# AT32F423xx_v2 register map
Vendor: Keil; Series: AT32F423; File version: 1.0
CPU: CM4 r0p1, little endian, no MPU, FPU, 4 interrupt priority bits
Registers are 32-bit, read-write, reset 0x0 unless marked. A register's access mark holds for its fields unless they carry their own. Offsets are from the block's base; [hi:lo] are bit positions.

## DEBUG — Debug support
Base 0xE0042000
0x00 IDCODE ro — DEBUG IDCODE
  [31:0] PID — Product ID
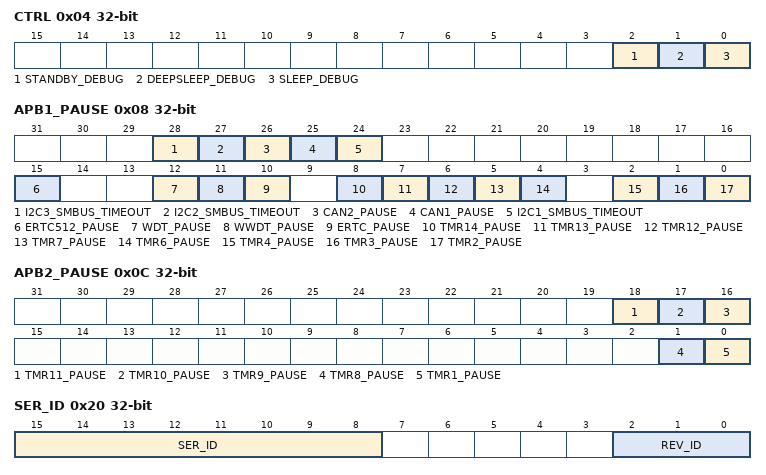
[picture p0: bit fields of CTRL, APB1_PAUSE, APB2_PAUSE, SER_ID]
0x04 CTRL — DEBUG CTRL
  [2] STANDBY_DEBUG, [1] DEEPSLEEP_DEBUG, [0] SLEEP_DEBUG
0x08 APB1_PAUSE — DEBUG APB1 PAUSE
  [28] I2C3_SMBUS_TIMEOUT, [27] I2C2_SMBUS_TIMEOUT, [26] CAN2_PAUSE, [25] CAN1_PAUSE, [24] I2C1_SMBUS_TIMEOUT, [15] ERTC512_PAUSE, [12] WDT_PAUSE, [11] WWDT_PAUSE, [10] ERTC_PAUSE, [8] TMR14_PAUSE, [7] TMR13_PAUSE, [6] TMR12_PAUSE, [5] TMR7_PAUSE, [4] TMR6_PAUSE, [2] TMR4_PAUSE, [1] TMR3_PAUSE, [0] TMR2_PAUSE
0x0C APB2_PAUSE — DEBUG APB2 PAUSE
  [18] TMR11_PAUSE, [17] TMR10_PAUSE, [16] TMR9_PAUSE, [1] TMR8_PAUSE, [0] TMR1_PAUSE
0x20 SER_ID ro — SERIES ID
  [15:8] SER_ID — series ID
  [2:0] REV_ID — version ID

## CRC — CRC calculation unit
Base 0x40023000
0x00 DT reset 0xFFFFFFFF — Data register
  [31:0] DT — Data Register
0x04 CDT — Common data register
  [0] CDT — Common Data
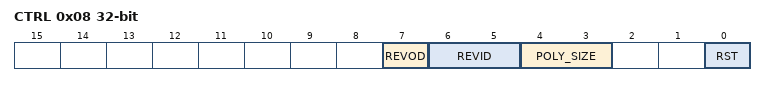
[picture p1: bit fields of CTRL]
0x08 CTRL — Control register
  [7] REVOD — Reverse output data
  [6:5] REVID — Reverse input data
  [4:3] POLY_SIZE — Polynomial size
  [0] RST — Reset bit
0x10 IDT reset 0xFFFFFFFF — Initial data register
  [31:0] IDT — Initial Data
0x14 POLY reset 0x4C11DB7 — Polynomial coefficient register
  [31:0] POLY — polynomial coefficient

## FLASH — Flash memory controler
Base 0x40023C00
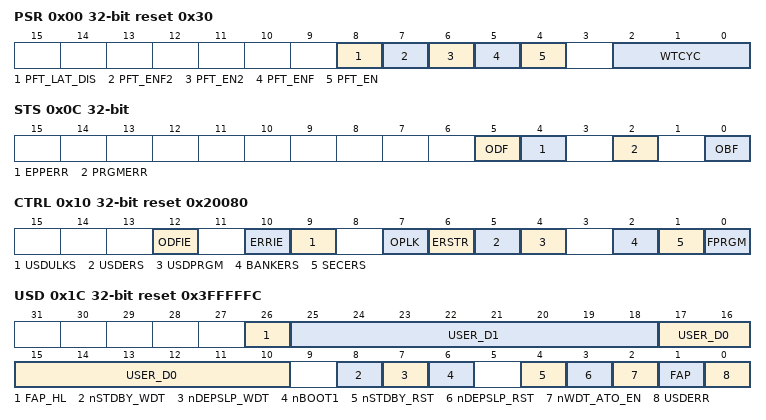
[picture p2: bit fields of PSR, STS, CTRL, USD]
0x00 PSR reset 0x30 — Performance selection register
  [8] PFT_LAT_DIS — Prefetch latency disable
  [7] PFT_ENF2 ro — Prefetch enabled flag 2
  [6] PFT_EN2 — Prefetch enable 2
  [5] PFT_ENF ro — Prefetch enabled flag
  [4] PFT_EN — Prefetch enable
  [2:0] WTCYC — Wait cycle
0x04 UNLOCK wo
  [31:0] UKVAL — Unlock key value
0x08 USD_UNLOCK wo
  [31:0] USD_UKVAL — User system data Unlock key value
0x0C STS — Status register
  [5] ODF — Operate done flag
  [4] EPPERR — Erase/program protection error
  [2] PRGMERR — program error
  [0] OBF ro — Operate busy flag
0x10 CTRL reset 0x20080 — Control register
  [12] ODFIE — Operation done flag interrupt enable
  [10] ERRIE — Error interrupt enable
  [9] USDULKS — User system data unlock success
  [7] OPLK — Operation lock
  [6] ERSTR — Erasing start
  [5] USDERS — User system data erase
  [4] USDPRGM — User system data program
  [2] BANKERS — Bank erase
  [1] SECERS — Sector erase
  [0] FPRGM — Flash program
0x14 ADDR wo — Address register
  [31:0] FA — Flash Address
0x1C USD ro reset 0x3FFFFFC — User system data register
  [26] FAP_HL — FAP high level
  [25:18] USER_D1 — User data 1
  [17:10] USER_D0 — User data 0
  [8] nSTDBY_WDT — Standby wdt stop count
  [7] nDEPSLP_WDT — Deepsleep wdt stop count
  [6] nBOOT1 — boot1
  [4] nSTDBY_RST — Standby reset
  [3] nDEPSLP_RST — Deepsleep reset
  [2] nWDT_ATO_EN — WDT auto enable
  [1] FAP — FLASH access protection
  [0] USDERR — User system data error
0x20 EPPS ro reset 0xFFFFFFFF — Erase/program protection status register
  [31:0] EPPS — Erase/program protection status
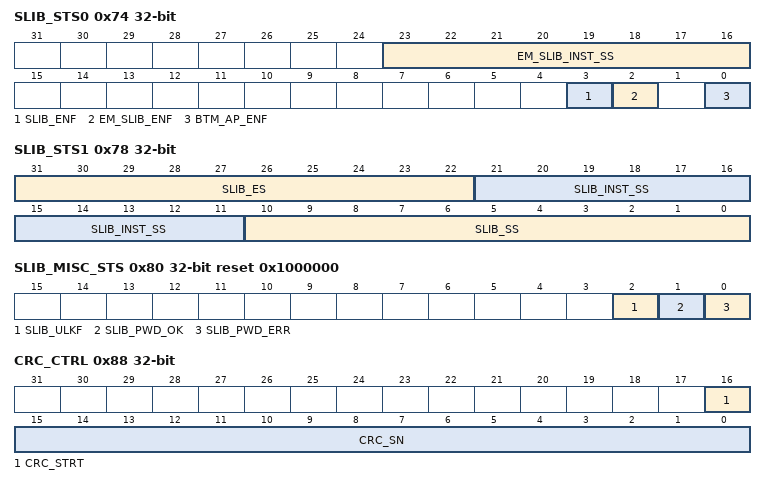
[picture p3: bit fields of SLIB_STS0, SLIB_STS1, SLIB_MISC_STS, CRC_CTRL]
0x74 SLIB_STS0 — sLib status 0 register
  [23:16] EM_SLIB_INST_SS — Extension memory sLib instruction start sector
  [3] SLIB_ENF — sLib enabled flag
  [2] EM_SLIB_ENF — Extension memory sLib enabled flag
  [0] BTM_AP_ENF — Boot memory store application code enabled flag
0x78 SLIB_STS1 — sLib status 1 register
  [31:22] SLIB_ES — sLib end sector
  [21:11] SLIB_INST_SS — sLib instruction start sector
  [10:0] SLIB_SS — sLib start sector
0x7C SLIB_PWD_CLR wo — SLIB password clear register
  [31:0] SLIB_PCLR_VAL — sLib password clear value
0x80 SLIB_MISC_STS reset 0x1000000 — sLib misc status register
  [2] SLIB_ULKF ro — sLib unlock flag
  [1] SLIB_PWD_OK ro — sLib password ok
  [0] SLIB_PWD_ERR ro — sLib password error
0x84 CRC_ADDR wo — Flash CRC data start address register
  [31:0] CRC_ADDR — CRC address
0x88 CRC_CTRL — Flash CRC controll register
  [16] CRC_STRT wo — CRC start
  [15:0] CRC_SN — CRC sector numbler
0x8C CRC_CHKR ro — FLASH CRC check result register
  [31:0] FCRC_OUT — CRC32 verification result of flash user code or SLIB code
0x160 SLIB_SET_PWD wo — sLib password setting register
  [31:0] SLIB_PSET_VAL — sLib password setting val
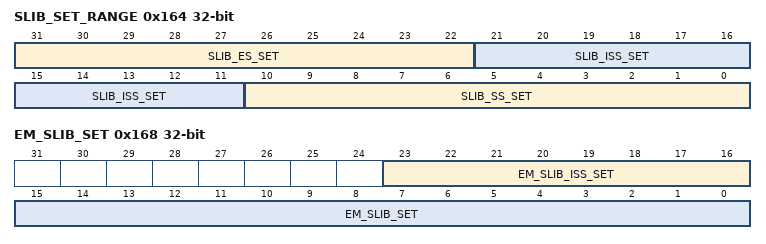
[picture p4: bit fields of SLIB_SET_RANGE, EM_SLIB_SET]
0x164 SLIB_SET_RANGE wo — Configure sLib range register
  [31:22] SLIB_ES_SET — sLib end sector setting
  [21:11] SLIB_ISS_SET — sLib instruction start sector setting
  [10:0] SLIB_SS_SET — sLib start sector setting
0x168 EM_SLIB_SET wo — Extension momery slib set register
  [23:16] EM_SLIB_ISS_SET — Extension memory sLib instruction start sector setting
  [15:0] EM_SLIB_SET — Extension memory sLib setting
0x16C BTM_MODE_SET wo — Boot memory mode setting register
  [7:0] BTM_MODE_SET — Boot memory mode setting
0x170 SLIB_UNLOCK wo
  [31:0] SLIB_UKVAL — sLib unlock key value

## Notices in the file
Copyright (C) 2012-2014 ARM Limited. All rights reserved.
Purpose: System Viewer Description (SVD) Example (Schema Version 1.1)
This is a description of a none-existent and incomplete device
for demonstration purposes only.
Redistribution and use in source and binary forms, with or without
modification, are permitted provided that the following conditions are met:
- Redistributions of source code must retain the above copyright
notice, this list of conditions and the following disclaimer.
- Redistributions in binary form must reproduce the above copyright
notice, this list of conditions and the following disclaimer in the
documentation and/or other materials provided with the distribution.
- Neither the name of ARM nor the names of its contributors may be used
to endorse or promote products derived from this software without
specific prior written permission.
THIS SOFTWARE IS PROVIDED BY THE COPYRIGHT HOLDERS AND CONTRIBUTORS "AS IS"
AND ANY EXPRESS OR IMPLIED WARRANTIES, INCLUDING, BUT NOT LIMITED TO, THE
IMPLIED WARRANTIES OF MERCHANTABILITY AND FITNESS FOR A PARTICULAR PURPOSE
ARE DISCLAIMED. IN NO EVENT SHALL COPYRIGHT HOLDERS AND CONTRIBUTORS BE
LIABLE FOR ANY DIRECT, INDIRECT, INCIDENTAL, SPECIAL, EXEMPLARY, OR
CONSEQUENTIAL DAMAGES (INCLUDING, BUT NOT LIMITED TO, PROCUREMENT OF
SUBSTITUTE GOODS OR SERVICES; LOSS OF USE, DATA, OR PROFITS; OR BUSINESS
INTERRUPTION) HOWEVER CAUSED AND ON ANY THEORY OF LIABILITY, WHETHER IN
CONTRACT, STRICT LIABILITY, OR TORT (INCLUDING NEGLIGENCE OR OTHERWISE)
ARISING IN ANY WAY OUT OF THE USE OF THIS SOFTWARE, EVEN IF ADVISED OF THE
POSSIBILITY OF SUCH DAMAGE.
